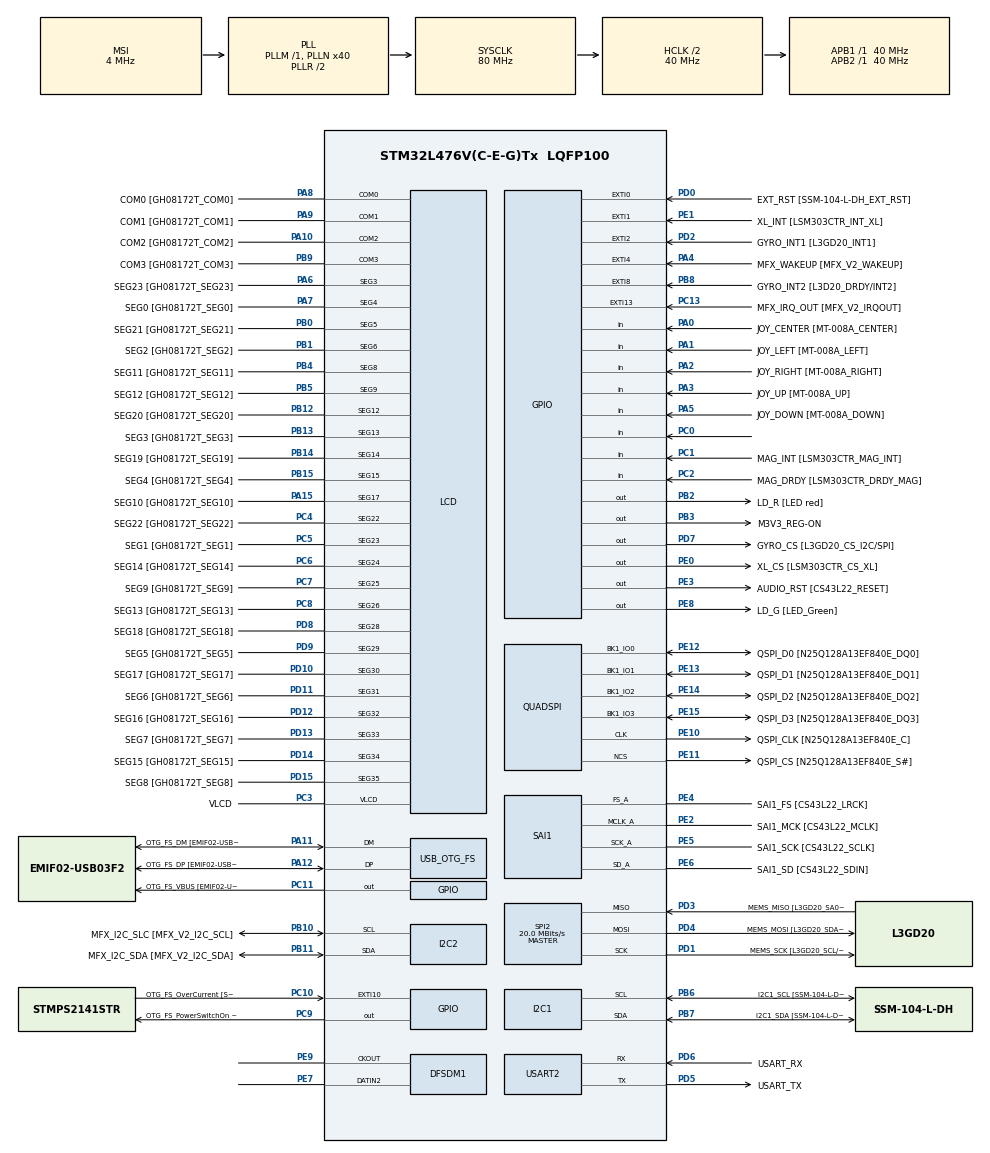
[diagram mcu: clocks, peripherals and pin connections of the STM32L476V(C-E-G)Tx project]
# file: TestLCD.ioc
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DFSDM1.Divider=4
DFSDM1.DmaMode_inj_FIL0=DISABLE
DFSDM1.DmaMode_reg_FIL0=ENABLE
DFSDM1.FastMode_reg_FIL0=ENABLE
DFSDM1.FilterOrder_CH2=DFSDM_CHANNEL_FASTSINC_ORDER
DFSDM1.Filter_injChannel2_FIL0=DFSDM_CHANNEL_2
DFSDM1.Filter_regChannel_FIL0=DFSDM_CHANNEL_2
DFSDM1.Fosr_FIL0=64
DFSDM1.Oversampling_CH2=10
DFSDM1.RightBitShift_CH2=2
DFSDM1.ScanMode_inj_FIL0=ENABLE
DFSDM1.Selection=DFSDM_CHANNEL_OUTPUT_CLOCK_AUDIO
DFSDM1.SincOrder_FIL0=DFSDM_FILTER_SINC3_ORDER
Dma.DFSDM1_FLT0.0.Direction=DMA_PERIPH_TO_MEMORY
Dma.DFSDM1_FLT0.0.Instance=DMA1_Channel4
Dma.DFSDM1_FLT0.0.MemDataAlignment=DMA_MDATAALIGN_WORD
Dma.DFSDM1_FLT0.0.MemInc=DMA_MINC_ENABLE
Dma.DFSDM1_FLT0.0.Mode=DMA_CIRCULAR
Dma.DFSDM1_FLT0.0.PeriphDataAlignment=DMA_PDATAALIGN_WORD
Dma.DFSDM1_FLT0.0.PeriphInc=DMA_PINC_DISABLE
Dma.DFSDM1_FLT0.0.Priority=DMA_PRIORITY_HIGH
Dma.Request0=DFSDM1_FLT0
Dma.Request1=SAI1_A
Dma.SAI1_A.1.Direction=DMA_MEMORY_TO_PERIPH
Dma.SAI1_A.1.Instance=DMA2_Channel1
Dma.SAI1_A.1.MemDataAlignment=DMA_MDATAALIGN_HALFWORD
Dma.SAI1_A.1.MemInc=DMA_MINC_ENABLE
Dma.SAI1_A.1.Mode=DMA_CIRCULAR
Dma.SAI1_A.1.PeriphDataAlignment=DMA_PDATAALIGN_HALFWORD
Dma.SAI1_A.1.PeriphInc=DMA_PINC_DISABLE
Dma.SAI1_A.1.Priority=DMA_PRIORITY_HIGH
I2C1.Timing=0x00909BEB
I2C2.Timing=0x00909BEB
Mcu.Family=STM32L4
Mcu.Name=STM32L476V(C-E-G)Tx
Mcu.Package=LQFP100
NVIC.DFSDM1_FLT0_IRQn=true\:0\:0\:false\:false\:true\:true\:true
NVIC.DMA1_Channel4_IRQn=true\:0\:0\:false\:false\:true\:false\:true
NVIC.DMA2_Channel1_IRQn=true\:0\:0\:false\:false\:true\:false\:true
NVIC.OTG_FS_IRQn=true\:0\:0\:false\:false\:true\:true\:true
NVIC.PriorityGroup=NVIC_PRIORITYGROUP_4
NVIC.QUADSPI_IRQn=true\:0\:0\:false\:false\:true\:true\:true
NVIC.SAI1_IRQn=true\:0\:0\:false\:false\:true\:true\:true
PA0.GPIO_Label=JOY_CENTER [MT-008A_CENTER]
PA0.GPIO_Mode=GPIO_MODE_INPUT
PA0.GPIO_PuPd=GPIO_PULLDOWN
PA0.Signal=GPIO_Input
PA1.GPIO_Label=JOY_LEFT [MT-008A_LEFT]
PA1.GPIO_Mode=GPIO_MODE_INPUT
PA1.GPIO_PuPd=GPIO_PULLDOWN
PA1.Signal=GPIO_Input
PA10.GPIO_Label=COM2 [GH08172T_COM2]
PA10.GPIO_Mode=GPIO_MODE_AF_PP
PA10.GPIO_PuPd=GPIO_NOPULL
PA10.GPIO_Speed=GPIO_SPEED_FREQ_LOW
PA10.Mode=1/4 Duty Cycle
PA10.Signal=LCD_COM2
PA11.GPIO_Label=OTG_FS_DM [EMIF02-USB03F2_D-out]
PA11.GPIO_Mode=GPIO_MODE_AF_PP
PA11.GPIO_PuPd=GPIO_NOPULL
PA11.GPIO_Speed=GPIO_SPEED_FREQ_VERY_HIGH
PA11.Mode=Host_Only
PA11.Signal=USB_OTG_FS_DM
PA12.GPIO_Label=OTG_FS_DP [EMIF02-USB03F2_D+out]
PA12.GPIO_Mode=GPIO_MODE_AF_PP
PA12.GPIO_PuPd=GPIO_NOPULL
PA12.GPIO_Speed=GPIO_SPEED_FREQ_VERY_HIGH
PA12.Mode=Host_Only
PA12.Signal=USB_OTG_FS_DP
PA13\ (JTMS-SWDIO).GPIO_Label=SWDIO
PA13\ (JTMS-SWDIO).Mode=Serial_Wire
PA13\ (JTMS-SWDIO).Signal=SYS_JTMS-SWDIO
PA14\ (JTCK-SWCLK).GPIO_Label=SWCLK
PA14\ (JTCK-SWCLK).Mode=Serial_Wire
PA14\ (JTCK-SWCLK).Signal=SYS_JTCK-SWCLK
PA15\ (JTDI).GPIO_Label=SEG10 [GH08172T_SEG10]
PA15\ (JTDI).GPIO_Mode=GPIO_MODE_AF_PP
PA15\ (JTDI).GPIO_PuPd=GPIO_NOPULL
PA15\ (JTDI).GPIO_Speed=GPIO_SPEED_FREQ_LOW
PA15\ (JTDI).Mode=SEG17
PA15\ (JTDI).Signal=LCD_SEG17
PA2.GPIO_Label=JOY_RIGHT [MT-008A_RIGHT]
PA2.GPIO_Mode=GPIO_MODE_INPUT
PA2.GPIO_PuPd=GPIO_PULLDOWN
PA2.Signal=GPIO_Input
PA3.GPIO_Label=JOY_UP [MT-008A_UP]
PA3.GPIO_Mode=GPIO_MODE_INPUT
PA3.GPIO_PuPd=GPIO_PULLDOWN
PA3.Signal=GPIO_Input
PA4.GPIO_Label=MFX_WAKEUP [MFX_V2_WAKEUP]
PA4.GPIO_ModeDefaultEXTI=GPIO_MODE_EVT_RISING
PA4.GPIO_PuPd=GPIO_NOPULL
PA4.Signal=GPXTI4
PA5.GPIO_Label=JOY_DOWN [MT-008A_DOWN]
PA5.GPIO_Mode=GPIO_MODE_INPUT
PA5.GPIO_PuPd=GPIO_PULLDOWN
PA5.Signal=GPIO_Input
PA6.GPIO_Label=SEG23 [GH08172T_SEG23]
PA6.GPIO_Mode=GPIO_MODE_AF_PP
PA6.GPIO_PuPd=GPIO_NOPULL
PA6.GPIO_Speed=GPIO_SPEED_FREQ_LOW
PA6.Mode=SEG3
PA6.Signal=LCD_SEG3
PA7.GPIO_Label=SEG0 [GH08172T_SEG0]
PA7.GPIO_Mode=GPIO_MODE_AF_PP
PA7.GPIO_PuPd=GPIO_NOPULL
PA7.GPIO_Speed=GPIO_SPEED_FREQ_LOW
PA7.Mode=SEG4
PA7.Signal=LCD_SEG4
PA8.GPIO_Label=COM0 [GH08172T_COM0]
PA8.GPIO_Mode=GPIO_MODE_AF_PP
PA8.GPIO_PuPd=GPIO_NOPULL
PA8.GPIO_Speed=GPIO_SPEED_FREQ_LOW
PA8.Mode=1/4 Duty Cycle
PA8.Signal=LCD_COM0
PA9.GPIO_Label=COM1 [GH08172T_COM1]
PA9.GPIO_Mode=GPIO_MODE_AF_PP
PA9.GPIO_PuPd=GPIO_NOPULL
PA9.GPIO_Speed=GPIO_SPEED_FREQ_LOW
PA9.Mode=1/4 Duty Cycle
PA9.Signal=LCD_COM1
PB0.GPIO_Label=SEG21 [GH08172T_SEG21]
PB0.GPIO_Mode=GPIO_MODE_AF_PP
PB0.GPIO_PuPd=GPIO_NOPULL
PB0.GPIO_Speed=GPIO_SPEED_FREQ_LOW
PB0.Mode=SEG5
PB0.Signal=LCD_SEG5
PB1.GPIO_Label=SEG2 [GH08172T_SEG2]
PB1.GPIO_Mode=GPIO_MODE_AF_PP
PB1.GPIO_PuPd=GPIO_NOPULL
PB1.GPIO_Speed=GPIO_SPEED_FREQ_LOW
PB1.Mode=SEG6
PB1.Signal=LCD_SEG6
PB10.GPIO_Label=MFX_I2C_SLC [MFX_V2_I2C_SCL]
PB10.GPIO_Mode=GPIO_MODE_AF_OD
PB10.GPIO_PuPdOD=GPIO_PULLUP
PB10.GPIO_Speed=GPIO_SPEED_FREQ_VERY_HIGH
PB10.Mode=I2C
PB10.Signal=I2C2_SCL
PB11.GPIO_Label=MFX_I2C_SDA [MFX_V2_I2C_SDA]
PB11.GPIO_Mode=GPIO_MODE_AF_OD
PB11.GPIO_PuPdOD=GPIO_PULLUP
PB11.GPIO_Speed=GPIO_SPEED_FREQ_VERY_HIGH
PB11.Mode=I2C
PB11.Signal=I2C2_SDA
PB12.GPIO_Label=SEG20 [GH08172T_SEG20]
PB12.GPIO_Mode=GPIO_MODE_AF_PP
PB12.GPIO_PuPd=GPIO_NOPULL
PB12.GPIO_Speed=GPIO_SPEED_FREQ_LOW
PB12.Mode=SEG12
PB12.Signal=LCD_SEG12
PB13.GPIO_Label=SEG3 [GH08172T_SEG3]
PB13.GPIO_Mode=GPIO_MODE_AF_PP
PB13.GPIO_PuPd=GPIO_NOPULL
PB13.GPIO_Speed=GPIO_SPEED_FREQ_LOW
PB13.Mode=SEG13
PB13.Signal=LCD_SEG13
PB14.GPIO_Label=SEG19 [GH08172T_SEG19]
PB14.GPIO_Mode=GPIO_MODE_AF_PP
PB14.GPIO_PuPd=GPIO_NOPULL
PB14.GPIO_Speed=GPIO_SPEED_FREQ_LOW
PB14.Mode=SEG14
PB14.Signal=LCD_SEG14
PB15.GPIO_Label=SEG4 [GH08172T_SEG4]
PB15.GPIO_Mode=GPIO_MODE_AF_PP
PB15.GPIO_PuPd=GPIO_NOPULL
PB15.GPIO_Speed=GPIO_SPEED_FREQ_LOW
PB15.Mode=SEG15
PB15.Signal=LCD_SEG15
PB2.GPIO_Label=LD_R [LED red]
PB2.GPIO_ModeDefaultOutputPP=GPIO_MODE_OUTPUT_PP
PB2.GPIO_PuPd=GPIO_PULLUP
PB2.GPIO_Speed=GPIO_SPEED_FREQ_VERY_HIGH
PB2.Signal=GPIO_Output
PB3\ (JTDO-TRACESWO).GPIO_Label=M3V3_REG-ON
PB3\ (JTDO-TRACESWO).GPIO_ModeDefaultOutputPP=GPIO_MODE_OUTPUT_PP
PB3\ (JTDO-TRACESWO).GPIO_PuPd=GPIO_NOPULL
PB3\ (JTDO-TRACESWO).GPIO_Speed=GPIO_SPEED_FREQ_LOW
PB3\ (JTDO-TRACESWO).Signal=GPIO_Output
PB4\ (NJTRST).GPIO_Label=SEG11 [GH08172T_SEG11]
PB4\ (NJTRST).GPIO_Mode=GPIO_MODE_AF_PP
PB4\ (NJTRST).GPIO_PuPd=GPIO_NOPULL
PB4\ (NJTRST).GPIO_Speed=GPIO_SPEED_FREQ_LOW
PB4\ (NJTRST).Mode=SEG8
PB4\ (NJTRST).Signal=LCD_SEG8
PB5.GPIO_Label=SEG12 [GH08172T_SEG12]
PB5.GPIO_Mode=GPIO_MODE_AF_PP
PB5.GPIO_PuPd=GPIO_NOPULL
PB5.GPIO_Speed=GPIO_SPEED_FREQ_LOW
PB5.Mode=SEG9
PB5.Signal=LCD_SEG9
PB6.GPIO_FM6=__NULL
PB6.GPIO_Label=I2C1_SCL [SSM-104-L-DH_SCL]
PB6.GPIO_Mode=GPIO_MODE_AF_OD
PB6.GPIO_PuPdOD=GPIO_PULLUP
PB6.GPIO_Speed=GPIO_SPEED_FREQ_VERY_HIGH
PB6.Mode=I2C
PB6.Signal=I2C1_SCL
PB7.GPIO_FM7=__NULL
PB7.GPIO_Label=I2C1_SDA [SSM-104-L-DH_SDA]
PB7.GPIO_Mode=GPIO_MODE_AF_OD
PB7.GPIO_PuPdOD=GPIO_PULLUP
PB7.GPIO_Speed=GPIO_SPEED_FREQ_VERY_HIGH
PB7.Mode=I2C
PB7.Signal=I2C1_SDA
PB8.GPIO_Label=GYRO_INT2 [L3D20_DRDY/INT2]
PB8.GPIO_ModeDefaultEXTI=GPIO_MODE_EVT_RISING
PB8.GPIO_PuPd=GPIO_NOPULL
PB8.Signal=GPXTI8
PB9.GPIO_FM9=__NULL
PB9.GPIO_Label=COM3 [GH08172T_COM3]
PB9.GPIO_Mode=GPIO_MODE_AF_PP
PB9.GPIO_PuPd=GPIO_NOPULL
PB9.GPIO_Speed=GPIO_SPEED_FREQ_LOW
PB9.Mode=1/4 Duty Cycle
PB9.Signal=LCD_COM3
PC0.Signal=GPIO_Input
PC1.GPIO_Label=MAG_INT [LSM303CTR_MAG_INT]
PC1.GPIO_Mode=GPIO_MODE_INPUT
PC1.GPIO_PuPd=GPIO_NOPULL
PC1.Signal=GPIO_Input
PC10.GPIO_Label=OTG_FS_OverCurrent [STMPS2141STR_FAULT]
PC10.GPIO_ModeDefaultEXTI=GPIO_MODE_EVT_RISING
PC10.GPIO_PuPd=GPIO_NOPULL
PC10.Signal=GPXTI10
PC11.GPIO_Label=OTG_FS_VBUS [EMIF02-USB03F2_Vbus]
PC11.GPIO_ModeDefaultOutputPP=GPIO_MODE_OUTPUT_PP
PC11.GPIO_PuPd=GPIO_NOPULL
PC11.GPIO_Speed=GPIO_SPEED_FREQ_LOW
PC11.Signal=GPIO_Output
PC13.GPIO_Label=MFX_IRQ_OUT [MFX_V2_IRQOUT]
PC13.GPIO_ModeDefaultEXTI=GPIO_MODE_EVT_RISING
PC13.GPIO_PuPd=GPIO_NOPULL
PC13.Signal=GPXTI13
PC14-OSC32_IN\ (PC14).Mode=LSE-External-Oscillator
PC14-OSC32_IN\ (PC14).Signal=RCC_OSC32_IN
PC15-OSC32_OUT\ (PC15).Mode=LSE-External-Oscillator
PC15-OSC32_OUT\ (PC15).Signal=RCC_OSC32_OUT
PC2.GPIO_Label=MAG_DRDY [LSM303CTR_DRDY_MAG]
PC2.GPIO_Mode=GPIO_MODE_INPUT
PC2.GPIO_PuPd=GPIO_NOPULL
PC2.Signal=GPIO_Input
PC3.GPIO_Label=VLCD
PC3.GPIO_Mode=GPIO_MODE_AF_PP
PC3.GPIO_PuPd=GPIO_NOPULL
PC3.GPIO_Speed=GPIO_SPEED_FREQ_LOW
PC3.Mode=1/4 Duty Cycle
PC3.Signal=LCD_VLCD
PC4.GPIO_Label=SEG22 [GH08172T_SEG22]
PC4.GPIO_Mode=GPIO_MODE_AF_PP
PC4.GPIO_PuPd=GPIO_NOPULL
PC4.GPIO_Speed=GPIO_SPEED_FREQ_LOW
PC4.Mode=SEG22
PC4.Signal=LCD_SEG22
PC5.GPIO_Label=SEG1 [GH08172T_SEG1]
PC5.GPIO_Mode=GPIO_MODE_AF_PP
PC5.GPIO_PuPd=GPIO_NOPULL
PC5.GPIO_Speed=GPIO_SPEED_FREQ_LOW
PC5.Mode=SEG23
PC5.Signal=LCD_SEG23
PC6.GPIO_Label=SEG14 [GH08172T_SEG14]
PC6.GPIO_Mode=GPIO_MODE_AF_PP
PC6.GPIO_PuPd=GPIO_NOPULL
PC6.GPIO_Speed=GPIO_SPEED_FREQ_LOW
PC6.Mode=SEG24
PC6.Signal=LCD_SEG24
PC7.GPIO_Label=SEG9 [GH08172T_SEG9]
PC7.GPIO_Mode=GPIO_MODE_AF_PP
PC7.GPIO_PuPd=GPIO_NOPULL
PC7.GPIO_Speed=GPIO_SPEED_FREQ_LOW
PC7.Mode=SEG25
PC7.Signal=LCD_SEG25
PC8.GPIO_Label=SEG13 [GH08172T_SEG13]
PC8.GPIO_Mode=GPIO_MODE_AF_PP
PC8.GPIO_PuPd=GPIO_NOPULL
PC8.GPIO_Speed=GPIO_SPEED_FREQ_LOW
PC8.Mode=SEG26
PC8.Signal=LCD_SEG26
PC9.GPIO_Label=OTG_FS_PowerSwitchOn [STMPS2141STR_EN]
PC9.GPIO_ModeDefaultOutputPP=GPIO_MODE_OUTPUT_PP
PC9.GPIO_PuPd=GPIO_NOPULL
PC9.GPIO_Speed=GPIO_SPEED_FREQ_LOW
PC9.PinState=GPIO_PIN_SET
PC9.Signal=GPIO_Output
PD0.GPIO_Label=EXT_RST [SSM-104-L-DH_EXT_RST]
PD0.GPIO_ModeDefaultEXTI=GPIO_MODE_EVT_RISING
PD0.GPIO_PuPd=GPIO_NOPULL
PD0.Signal=GPXTI0
PD1.GPIO_Label=MEMS_SCK [L3GD20_SCL/SPC]
PD1.GPIO_Mode=GPIO_MODE_AF_PP
PD1.GPIO_PuPd=GPIO_NOPULL
PD1.GPIO_Speed=GPIO_SPEED_FREQ_VERY_HIGH
PD1.Mode=Full_Duplex_Master
PD1.Signal=SPI2_SCK
PD10.GPIO_Label=SEG17 [GH08172T_SEG17]
PD10.GPIO_Mode=GPIO_MODE_AF_PP
PD10.GPIO_PuPd=GPIO_NOPULL
PD10.GPIO_Speed=GPIO_SPEED_FREQ_LOW
PD10.Mode=SEG30
PD10.Signal=LCD_SEG30
PD11.GPIO_Label=SEG6 [GH08172T_SEG6]
PD11.GPIO_Mode=GPIO_MODE_AF_PP
PD11.GPIO_PuPd=GPIO_NOPULL
PD11.GPIO_Speed=GPIO_SPEED_FREQ_LOW
PD11.Mode=SEG31
PD11.Signal=LCD_SEG31
PD12.GPIO_Label=SEG16 [GH08172T_SEG16]
PD12.GPIO_Mode=GPIO_MODE_AF_PP
PD12.GPIO_PuPd=GPIO_NOPULL
PD12.GPIO_Speed=GPIO_SPEED_FREQ_LOW
PD12.Mode=SEG32
PD12.Signal=LCD_SEG32
PD13.GPIO_Label=SEG7 [GH08172T_SEG7]
PD13.GPIO_Mode=GPIO_MODE_AF_PP
PD13.GPIO_PuPd=GPIO_NOPULL
PD13.GPIO_Speed=GPIO_SPEED_FREQ_LOW
PD13.Mode=SEG33
PD13.Signal=LCD_SEG33
PD14.GPIO_Label=SEG15 [GH08172T_SEG15]
PD14.GPIO_Mode=GPIO_MODE_AF_PP
PD14.GPIO_PuPd=GPIO_NOPULL
PD14.GPIO_Speed=GPIO_SPEED_FREQ_LOW
PD14.Mode=SEG34
PD14.Signal=LCD_SEG34
PD15.GPIO_Label=SEG8 [GH08172T_SEG8]
PD15.GPIO_Mode=GPIO_MODE_AF_PP
PD15.GPIO_PuPd=GPIO_NOPULL
PD15.GPIO_Speed=GPIO_SPEED_FREQ_LOW
PD15.Mode=SEG35
PD15.Signal=LCD_SEG35
PD2.GPIO_Label=GYRO_INT1 [L3GD20_INT1]
PD2.GPIO_ModeDefaultEXTI=GPIO_MODE_EVT_RISING
PD2.GPIO_PuPd=GPIO_NOPULL
PD2.Signal=GPXTI2
PD3.GPIO_Label=MEMS_MISO [L3GD20_SA0/SDO]
PD3.GPIO_Mode=GPIO_MODE_AF_PP
PD3.GPIO_PuPd=GPIO_NOPULL
PD3.GPIO_Speed=GPIO_SPEED_FREQ_VERY_HIGH
PD3.Mode=Full_Duplex_Master
PD3.Signal=SPI2_MISO
PD4.GPIO_Label=MEMS_MOSI [L3GD20_SDA/SDI/SDO]
PD4.GPIO_Mode=GPIO_MODE_AF_PP
PD4.GPIO_PuPd=GPIO_NOPULL
PD4.GPIO_Speed=GPIO_SPEED_FREQ_VERY_HIGH
PD4.Mode=Full_Duplex_Master
PD4.Signal=SPI2_MOSI
PD5.GPIO_Label=USART_TX
PD5.GPIO_Mode=GPIO_MODE_AF_PP
PD5.GPIO_PuPd=GPIO_PULLUP
PD5.GPIO_Speed=GPIO_SPEED_FREQ_VERY_HIGH
PD5.Mode=Asynchronous
PD5.Signal=USART2_TX
PD6.GPIO_Label=USART_RX
PD6.GPIO_Mode=GPIO_MODE_AF_PP
PD6.GPIO_PuPd=GPIO_PULLUP
PD6.GPIO_Speed=GPIO_SPEED_FREQ_VERY_HIGH
PD6.Mode=Asynchronous
PD6.Signal=USART2_RX
PD7.GPIO_Label=GYRO_CS [L3GD20_CS_I2C/SPI]
PD7.GPIO_ModeDefaultOutputPP=GPIO_MODE_OUTPUT_PP
PD7.GPIO_PuPd=GPIO_NOPULL
PD7.GPIO_Speed=GPIO_SPEED_FREQ_VERY_HIGH
PD7.Signal=GPIO_Output
PD8.GPIO_Label=SEG18 [GH08172T_SEG18]
PD8.GPIO_Mode=GPIO_MODE_AF_PP
PD8.GPIO_PuPd=GPIO_NOPULL
PD8.GPIO_Speed=GPIO_SPEED_FREQ_LOW
PD8.Mode=SEG28
PD8.Signal=LCD_SEG28
PD9.GPIO_Label=SEG5 [GH08172T_SEG5]
PD9.GPIO_Mode=GPIO_MODE_AF_PP
PD9.GPIO_PuPd=GPIO_NOPULL
PD9.GPIO_Speed=GPIO_SPEED_FREQ_LOW
PD9.Mode=SEG29
PD9.Signal=LCD_SEG29
PE0.GPIO_Label=XL_CS [LSM303CTR_CS_XL]
PE0.GPIO_ModeDefaultOutputPP=GPIO_MODE_OUTPUT_PP
PE0.GPIO_PuPd=GPIO_NOPULL
PE0.GPIO_Speed=GPIO_SPEED_FREQ_LOW
PE0.Signal=GPIO_Output
PE1.GPIO_Label=XL_INT [LSM303CTR_INT_XL]
PE1.GPIO_ModeDefaultEXTI=GPIO_MODE_EVT_RISING
PE1.GPIO_PuPd=GPIO_NOPULL
PE1.Signal=GPXTI1
PE10.GPIO_Label=QSPI_CLK [N25Q128A13EF840E_C]
PE10.GPIO_Mode=GPIO_MODE_AF_PP
PE10.GPIO_PuPd=GPIO_NOPULL
PE10.GPIO_Speed=GPIO_SPEED_FREQ_VERY_HIGH
PE10.Mode=Single Bank
PE10.Signal=QUADSPI_CLK
PE11.GPIO_Label=QSPI_CS [N25Q128A13EF840E_S\#]
PE11.GPIO_Mode=GPIO_MODE_AF_PP
PE11.GPIO_PuPd=GPIO_NOPULL
PE11.GPIO_Speed=GPIO_SPEED_FREQ_VERY_HIGH
PE11.Mode=Single Bank
PE11.Signal=QUADSPI_NCS
PE12.GPIO_Label=QSPI_D0 [N25Q128A13EF840E_DQ0]
PE12.GPIO_Mode=GPIO_MODE_AF_PP
PE12.GPIO_PuPd=GPIO_NOPULL
PE12.GPIO_Speed=GPIO_SPEED_FREQ_VERY_HIGH
PE12.Mode=Single Bank
PE12.Signal=QUADSPI_BK1_IO0
PE13.GPIO_Label=QSPI_D1 [N25Q128A13EF840E_DQ1]
PE13.GPIO_Mode=GPIO_MODE_AF_PP
PE13.GPIO_PuPd=GPIO_NOPULL
PE13.GPIO_Speed=GPIO_SPEED_FREQ_VERY_HIGH
PE13.Mode=Single Bank
PE13.Signal=QUADSPI_BK1_IO1
PE14.GPIO_Label=QSPI_D2 [N25Q128A13EF840E_DQ2]
PE14.GPIO_Mode=GPIO_MODE_AF_PP
PE14.GPIO_PuPd=GPIO_NOPULL
PE14.GPIO_Speed=GPIO_SPEED_FREQ_VERY_HIGH
PE14.Mode=Single Bank
PE14.Signal=QUADSPI_BK1_IO2
PE15.GPIO_Label=QSPI_D3 [N25Q128A13EF840E_DQ3]
PE15.GPIO_Mode=GPIO_MODE_AF_PP
PE15.GPIO_PuPd=GPIO_NOPULL
PE15.GPIO_Speed=GPIO_SPEED_FREQ_VERY_HIGH
PE15.Mode=Single Bank
PE15.Signal=QUADSPI_BK1_IO3
PE2.GPIO_Label=SAI1_MCK [CS43L22_MCLK]
PE2.GPIO_Mode=GPIO_MODE_AF_PP
PE2.GPIO_PuPd=GPIO_NOPULL
PE2.GPIO_Speed=GPIO_SPEED_FREQ_VERY_HIGH
PE2.Mode=SAI_A_MasterWithClock
PE2.Signal=SAI1_MCLK_A
PE3.GPIO_Label=AUDIO_RST [CS43L22_RESET]
PE3.GPIO_ModeDefaultOutputPP=GPIO_MODE_OUTPUT_PP
PE3.GPIO_PuPd=GPIO_NOPULL
PE3.GPIO_Speed=GPIO_SPEED_FREQ_HIGH
PE3.Signal=GPIO_Output
PE4.GPIO_Label=SAI1_FS [CS43L22_LRCK]
PE4.GPIO_Mode=GPIO_MODE_AF_PP
PE4.GPIO_PuPd=GPIO_NOPULL
PE4.GPIO_Speed=GPIO_SPEED_FREQ_VERY_HIGH
PE4.Mode=SAI_A_MasterWithClock
PE4.Signal=SAI1_FS_A
PE5.GPIO_Label=SAI1_SCK [CS43L22_SCLK]
PE5.GPIO_Mode=GPIO_MODE_AF_PP
PE5.GPIO_PuPd=GPIO_NOPULL
PE5.GPIO_Speed=GPIO_SPEED_FREQ_VERY_HIGH
PE5.Mode=SAI_A_MasterWithClock
PE5.Signal=SAI1_SCK_A
PE6.GPIO_Label=SAI1_SD [CS43L22_SDIN]
PE6.GPIO_Mode=GPIO_MODE_AF_PP
PE6.GPIO_PuPd=GPIO_NOPULL
PE6.GPIO_Speed=GPIO_SPEED_FREQ_VERY_HIGH
PE6.Mode=SAI_A_MasterWithClock
PE6.Signal=SAI1_SD_A
PE7.Signal=S_DATAIN2DFSDM1
PE8.GPIO_Label=LD_G [LED_Green]
PE8.GPIO_ModeDefaultOutputPP=GPIO_MODE_OUTPUT_PP
PE8.GPIO_PuPd=GPIO_PULLUP
PE8.GPIO_Speed=GPIO_SPEED_FREQ_VERY_HIGH
PE8.Signal=GPIO_Output
PE9.Signal=S_CKOUTDFSDM1
PH0-OSC_IN\ (PH0).Mode=HSE-External-Oscillator
PH0-OSC_IN\ (PH0).Signal=RCC_OSC_IN
PH1-OSC_OUT\ (PH1).Mode=HSE-External-Oscillator
PH1-OSC_OUT\ (PH1).Signal=RCC_OSC_OUT
ProjectManager.HeapSize=0x200
ProjectManager.StackSize=0x400
ProjectManager.TargetToolchain=STM32CubeIDE
QUADSPI.ChipSelectHighTime-Single\ Bank=QSPI_CS_HIGH_TIME_1_CYCLE
QUADSPI.ClockMode-Single\ Bank=QSPI_CLOCK_MODE_0
QUADSPI.ClockPrescaler-Single\ Bank=0
QUADSPI.FifoThreshold-Single\ Bank=4
QUADSPI.FlashSize-Single\ Bank=24
QUADSPI.SampleShifting-Single\ Bank=QSPI_SAMPLE_SHIFTING_HALFCYCLE
RCC.ADCFreq_Value=96000000
RCC.AHBCLKDivider=RCC_SYSCLK_DIV2
RCC.AHBFreq_Value=40000000
RCC.APB1Freq_Value=40000000
RCC.APB1TimFreq_Value=40000000
RCC.APB2Freq_Value=40000000
RCC.APB2TimFreq_Value=40000000
RCC.CortexFreq_Value=40000000
RCC.HCLKFreq_Value=40000000
RCC.HSE_VALUE=8000000
RCC.HSI_VALUE=16000000
RCC.MSI_VALUE=4000000
RCC.PLLN=40
RCC.PLLQ=RCC_PLLQ_DIV4
RCC.PLLSAI1N=48
RCC.PLLSAI1P=RCC_PLLP_DIV17
RCC.PLLSAI1Q=RCC_PLLQ_DIV4
RCC.PREFETCH_ENABLE=1
RCC.SYSCLKFreq_VALUE=80000000
RCC.SYSCLKSource=RCC_SYSCLKSOURCE_PLLCLK
RCC.USBFreq_Value=48000000
RCC.VCOOutputFreq_Value=160000000
SAI1.ActiveFrameLength-SAI_A_MasterWithClock=16
SAI1.AudioFrequency-SAI_A_MasterWithClock=SAI_AUDIO_FREQUENCY_44K
SAI1.DataSize-SAI_A_MasterWithClock=SAI_DATASIZE_16
SAI1.ErrorAudioFreq-SAI_A_MasterWithClock=0.26 %
SAI1.FIFOThreshold-SAI_A_MasterWithClock=SAI_FIFOTHRESHOLD_1QF
SAI1.FSDefinition-SAI_A_MasterWithClock=SAI_FS_CHANNEL_IDENTIFICATION
SAI1.FSOffset-SAI_A_MasterWithClock=SAI_FS_BEFOREFIRSTBIT
SAI1.FrameLength-SAI_A_MasterWithClock=32
SAI1.Instance-SAI_A_MasterWithClock=SAI$Index_Block_A
SAI1.MClockEnable-SAI_A_MasterWithClock=SAI_MASTERCLOCK_ENABLE
SAI1.MonoStereoMode-SAI_A_MasterWithClock=SAI_STEREOMODE
SAI1.OutputDrive-SAI_A_MasterWithClock=SAI_OUTPUTDRIVE_ENABLE
SAI1.RealAudioFreq-SAI_A_MasterWithClock=44.117 KHz
SAI1.SlotActive-SAI_A_MasterWithClock=0x00000003
SAI1.SlotNumber-SAI_A_MasterWithClock=2
SAI1.VirtualMode-SAI_A_MasterWithClock=VM_MASTER
SAI1.VirtualSlotActive-SAI_A_MasterWithClock=SAI_SLOT_USERSETTING
SAI1.VirtualSlotActive0-SAI_A_MasterWithClock=true
SAI1.VirtualSlotActive1-SAI_A_MasterWithClock=true
SH.S_CKOUTDFSDM1.0=DFSDM1_CKOUT,PDM_SPI_input_from_ch2_and_internal_clock
SH.S_DATAIN2DFSDM1.0=DFSDM1_DATIN2,PDM_SPI_input_from_ch2_and_internal_clock
SPI2.CalculateBaudRate=20.0 MBits/s
SPI2.Direction=SPI_DIRECTION_2LINES
SPI2.Mode=SPI_MODE_MASTER
SPI2.VirtualType=VM_MASTER
USART2.VirtualMode-Asynchronous=VM_ASYNC
USB_HOST.BSP.number=1
USB_HOST.USBH_HandleTypeDef=hUsbHostFS
USB_HOST.VirtualModeFS=Cdc
USB_HOST0.BSP.STBoard=false
USB_HOST0.BSP.api=Unknown
USB_HOST0.BSP.i2caddr=0
USB_HOST0.BSP.i2creg=0
USB_HOST0.BSP.instance=PC9
USB_HOST0.BSP.ip=GPIO
USB_HOST0.BSP.mode=Output
USB_HOST0.BSP.name=Drive_VBUS_FS
USB_HOST0.BSP.solution=PC9
USB_OTG_FS.VirtualMode=Host_Only
USB_OTG_FS.phy_itface=HCD_PHY_EMBEDDED
VP_USB_HOST_VS_USB_HOST_CDC_FS.Mode=CDC_FS
board=STM32L476G-DISCO

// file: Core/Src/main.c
/* USER CODE BEGIN Header */
/**
  ******************************************************************************
  * @file           : main.c
  * @brief          : Main program body
  ******************************************************************************
  * @attention
  *
  * <h2><center>&copy; Copyright (c) 2022 STMicroelectronics.
  * All rights reserved.</center></h2>
  *
  * This software component is licensed by ST under Ultimate Liberty license
  * SLA0044, the "License"; You may not use this file except in compliance with
  * the License. You may obtain a copy of the License at:
  *                             www.st.com/SLA0044
  *
  ******************************************************************************
  */
/* USER CODE END Header */
#include "main.h"
#include "dfsdm.h"
#include "dma.h"
#include "i2c.h"
#include "lcd.h"
#include "quadspi.h"
#include "sai.h"
#include "spi.h"
#include "usart.h"
#include "usb_host.h"
#include "gpio.h"

/* USER CODE BEGIN Includes */
#include "stm32l476g_discovery_glass_lcd.h"
#include "audio.h"
#include "cs43l22.h"
#include "stm32l476g_discovery_qspi.h"
#include "stm32l476g_discovery.h"
#include "string.h"
/* USER CODE END Includes */

/* USER CODE BEGIN PD */
#define SaturaLH(N, L, H) (((N)<(L))?(L):(((N)>(H))?(H):(N)))
#define BUFFER_SIZE         ((uint32_t)0x800) // 2048 bajtów
#define WRITE_READ_ADDR     ((uint32_t)0x0000)
#define QSPI_BASE_ADDR      ((uint32_t)0x90000000)
/* USER CODE END PD */

/* USER CODE BEGIN PV */
AUDIO_DrvTypeDef            *audio_drv;
uint32_t                     DmaRecHalfBuffCplt  = 0;
uint32_t                     DmaRecBuffCplt      = 0;
extern DFSDM_Filter_HandleTypeDef hdfsdm1_filter0;
extern DFSDM_Channel_HandleTypeDef hdfsdm1_channel2;
extern SAI_HandleTypeDef hsai_BlockA1;
extern DMA_HandleTypeDef hdma_sai1_a;
int32_t                      RecBuff[2048];
int16_t                      PlayBuff[4096];
int16_t 					filter_arr[4096];
uint32_t                     PlaybackStarted         = 0;
volatile int 				tryb = -1;//
int flag = 0;
static QSPI_Info pQSPI_Info;

/* USER CODE END PV */

void SystemClock_Config(void);
void MX_USB_HOST_Process(void);

int main(void)
{
  /* USER CODE BEGIN 1 */
  uint32_t i;
  int index_cpy = 0;
  /* USER CODE END 1 */

  /* MCU Configuration--------------------------------------------------------*/

  /* Reset of all peripherals, Initializes the Flash interface and the Systick. */
  HAL_Init();

  /* Configure the system clock */
  SystemClock_Config();

  /* USER CODE BEGIN SysInit */
  MX_DMA_Init();
  /* USER CODE END SysInit */

  /* Initialize all configured peripherals */
  MX_GPIO_Init();
  //MX_DMA_Init();
  MX_I2C1_Init();
  MX_I2C2_Init();
  MX_LCD_Init();
  MX_QUADSPI_Init();
  MX_SAI1_Init();
  MX_SPI2_Init();
  MX_USART2_UART_Init();
  MX_USB_HOST_Init();
  MX_DFSDM1_Init();
  /* USER CODE BEGIN 2 */
  if(HAL_OK != HAL_DFSDM_FilterRegularStart_DMA(&hdfsdm1_filter0, RecBuff, 2048))
    {
         Error_Handler();
     }

  __HAL_SAI_ENABLE(&hsai_BlockA1);

      if(CS43L22_ID != cs43l22_drv.ReadID(AUDIO_I2C_ADDRESS))
        {
          Error_Handler();
        }
      	audio_drv = &cs43l22_drv;
        audio_drv->Reset(AUDIO_I2C_ADDRESS);
        if(0 != audio_drv->Init(AUDIO_I2C_ADDRESS, OUTPUT_DEVICE_HEADPHONE, 90, AUDIO_FREQUENCY_44K))
        {
          Error_Handler();
        }

        BSP_LCD_GLASS_Init();

        if (QSPI_OK == BSP_QSPI_Init())
        {
      	  pQSPI_Info.FlashSize          = (uint32_t)0x00;
      	  pQSPI_Info.EraseSectorSize    = (uint32_t)0x00;
      	  pQSPI_Info.EraseSectorsNumber = (uint32_t)0x00;
      	  pQSPI_Info.ProgPageSize       = (uint32_t)0x00;
      	  pQSPI_Info.ProgPagesNumber    = (uint32_t)0x00;
      	  /* Read the QSPI memory info */
      	  BSP_QSPI_GetInfo(&pQSPI_Info);

      	  /* Test the correctness */
      	  if((pQSPI_Info.FlashSize != 0x1000000) || (pQSPI_Info.EraseSectorSize != 0x1000)  ||
      	    (pQSPI_Info.ProgPageSize != 0x100)  || (pQSPI_Info.EraseSectorsNumber != 4096) ||
      	    (pQSPI_Info.ProgPagesNumber != 65536))
      	  {
      		  BSP_LCD_GLASS_ScrollSentence((uint8_t *)"      QSPI GET INFO : FAILED.", 1, SCROLL_SPEED_HIGH);
      	  }
      	  else
      	  {
      		  /*##-3- Erase QSPI memory ################################################*/
      		  if(BSP_QSPI_Erase_Block(WRITE_READ_ADDR) != QSPI_OK)
      		  {
      			  BSP_LCD_GLASS_ScrollSentence((uint8_t *)"      QSPI ERASE : FAILED.", 1, SCROLL_SPEED_HIGH);
      	      }
      	  }
        }

        int index = 0; //ilosc wiadomosci

      //  BSP_QSPI_Erase_Chip();

//      for (uint32_t l = 0; l < 256; l++){
//
//        if(BSP_QSPI_Erase_Sector(l) != QSPI_OK)
//        {
//      	  Error_Handler();
//        }
//      }

  /* USER CODE END 2 */

  /* Infinite loop */
  /* USER CODE BEGIN WHILE */
  while (1)
  {

	  if (tryb == -1)
	  {
		  BSP_LCD_GLASS_DisplayString((uint8_t *)"WITAM");
	  }
      	  switch(BSP_JOY_GetState())
      	  {
      	  case JOY_DOWN: //tryb odtwarzania
      		  tryb = 0;
      		  break;
      	  case JOY_UP:
      		  tryb = 1;
      		  break;
      	  }
      	  while(tryb == 0) // nagrywanie
      	  {
      		  BSP_LCD_GLASS_DisplayString("NAGRAJ");
      		  if(BSP_JOY_GetState() == JOY_SEL)
      		  {
      			  BSP_LCD_GLASS_Clear();
      			  tryb = 3; // wybranie slota albo zaczecie nagrywania
      			  HAL_Delay(200);
      		  }
      		  else if (BSP_JOY_GetState() == JOY_DOWN || BSP_JOY_GetState() == JOY_UP)
      		  {
      			  tryb = 1;
      			  HAL_Delay(200);
      		  }
      	  }
      	  while(tryb == 1) //odtwarzanie
      	  {
      		  BSP_LCD_GLASS_DisplayString("ODTWORZ");
      		  if(BSP_JOY_GetState() == JOY_SEL)
      		  {
      			  BSP_LCD_GLASS_Clear();
      			  tryb = 2; // wybranie wiadomości
      			  HAL_Delay(200);
      		  }
      		  else if (BSP_JOY_GetState() == JOY_DOWN || BSP_JOY_GetState() == JOY_UP)
      		  {
      			  tryb = 0;
      			  HAL_Delay(200);
      		  }
      	  }
      	  while(tryb == 2)
      	  {
      		 if (index == 0)
      		 {
      			 BSP_LCD_GLASS_ScrollSentence((uint8_t *)"      NIE MA WIADOMOSCI.", 1, SCROLL_SPEED_HIGH);
      			 tryb = 1;
      		 }
      		  uint8_t str_index[8];
      		  sprintf(str_index, "Wiad %d", index_cpy);
      		  BSP_LCD_GLASS_DisplayString(str_index);
      		  if(BSP_JOY_GetState() == JOY_UP)
      		  {
      			  if(index_cpy < 9 && index_cpy < index)
      			  {
      				  index_cpy++;
      				  HAL_Delay(200);
      				BSP_LCD_GLASS_Clear();
      			  }
      		  }
      		  if(BSP_JOY_GetState() == JOY_DOWN)
      		  {
      			  if(index_cpy > 1)
      			  {
      				  index_cpy--;
      				  HAL_Delay(200);

      			  }
      		  }

      		  if(BSP_JOY_GetState() == JOY_LEFT)
      		  {
      		 	BSP_LCD_GLASS_Clear();
      		 	tryb = 1;
      		  }

      		  if(BSP_JOY_GetState() == JOY_SEL)
      			 {
      			  for(int j = 0; j<100; j++)
      			  {
      				BSP_QSPI_Read(PlayBuff, WRITE_READ_ADDR+(BUFFER_SIZE*j)+(index_cpy-1)*BUFFER_SIZE*2, 2*BUFFER_SIZE);
      				if(PlaybackStarted == 0)
      				{
      					if(HAL_OK != HAL_SAI_Transmit_DMA(&hsai_BlockA1, (uint8_t *) &PlayBuff[0], 2*BUFFER_SIZE))
      					{
      						Error_Handler();
      					}
      					if(0 != audio_drv->Play(AUDIO_I2C_ADDRESS, (uint16_t *) &PlayBuff[0], 2*BUFFER_SIZE))
      					{
      						Error_Handler();
      					}
      					PlaybackStarted = 1;
      				}
      			  }
      			if(0 != audio_drv->Stop(AUDIO_I2C_ADDRESS, CODEC_PDWN_HW))
      					{
      				Error_Handler();
      					}
      			if(HAL_SAI_DMAStop(&hsai_BlockA1) != HAL_OK)
      			{
      				Error_Handler();
      			}
      			PlaybackStarted = 0;
      			  tryb = 1;
      			 }
      	  }
      	  while(tryb == 3)
      	  {
      		  if(BSP_JOY_GetState() == JOY_LEFT)
      		  {
      			  BSP_LCD_GLASS_Clear();
      			  tryb = 1;
      		  }

      		BSP_LCD_GLASS_ScrollSentence((uint8_t *)"      NAGRANIE.", 1, SCROLL_SPEED_HIGH);
      		BSP_LCD_GLASS_ScrollSentence((uint8_t *)"      NAGRANIE.", 1, SCROLL_SPEED_HIGH);
      		BSP_LCD_GLASS_ScrollSentence((uint8_t *)"      NAGRANIE.", 1, SCROLL_SPEED_HIGH);

      		for(int k = 0; k < 100; k++)
      		{
      		if(DmaRecHalfBuffCplt == 1)
      		{
      		      				      /* Store values on Play buff */
      			for(i = 0; i < BUFFER_SIZE/2; i++)
      			{
      				filter_arr[2*i]     = SaturaLH((RecBuff[i] >> 8), -32768, 32767);
      				filter_arr[(2*i)+1] = filter_arr[2*i];
      			}

      			DmaRecHalfBuffCplt  = 0;
      		}
      		if(DmaRecBuffCplt == 1)
      		{
      			/* Store values on Play buff */
      			for(i = BUFFER_SIZE/2; i < BUFFER_SIZE; i++)
      			{
      				filter_arr[2*i]     = SaturaLH((RecBuff[i] >> 8), -32768, 32767);
      				filter_arr[(2*i)+1] = filter_arr[2*i];
      			}

      			DmaRecBuffCplt  = 0;
      		}
      		if (BSP_QSPI_Write(filter_arr, WRITE_READ_ADDR+(BUFFER_SIZE*k*2)+index*100*2*BUFFER_SIZE, BUFFER_SIZE*2) != QSPI_OK) Error_Handler();
      		}

      		BSP_LED_On(LED_GREEN);
      		HAL_Delay(1000);
      		BSP_LED_Off(LED_GREEN);

      		tryb = 1;
      		index++;
      		index_cpy = index;
      	  }

        /* USER CODE END 3 */
      }
  /* USER CODE END 3 */
}

void SystemClock_Config(void)
{
  RCC_OscInitTypeDef RCC_OscInitStruct = {0};
  RCC_ClkInitTypeDef RCC_ClkInitStruct = {0};
  RCC_PeriphCLKInitTypeDef PeriphClkInit = {0};

  /** Configure LSE Drive Capability
  */
  HAL_PWR_EnableBkUpAccess();
  __HAL_RCC_LSEDRIVE_CONFIG(RCC_LSEDRIVE_LOW);
  /** Initializes the RCC Oscillators according to the specified parameters
  * in the RCC_OscInitTypeDef structure.
  */
  RCC_OscInitStruct.OscillatorType = RCC_OSCILLATORTYPE_LSI|RCC_OSCILLATORTYPE_LSE
                              |RCC_OSCILLATORTYPE_MSI;
  RCC_OscInitStruct.LSEState = RCC_LSE_ON;
  RCC_OscInitStruct.LSIState = RCC_LSI_ON;
  RCC_OscInitStruct.MSIState = RCC_MSI_ON;
  RCC_OscInitStruct.MSICalibrationValue = 0;
  RCC_OscInitStruct.MSIClockRange = RCC_MSIRANGE_6;
  RCC_OscInitStruct.PLL.PLLState = RCC_PLL_ON;
  RCC_OscInitStruct.PLL.PLLSource = RCC_PLLSOURCE_MSI;
  RCC_OscInitStruct.PLL.PLLM = 1;
  RCC_OscInitStruct.PLL.PLLN = 40;
  RCC_OscInitStruct.PLL.PLLP = RCC_PLLP_DIV7;
  RCC_OscInitStruct.PLL.PLLQ = RCC_PLLQ_DIV4;
  RCC_OscInitStruct.PLL.PLLR = RCC_PLLR_DIV2;
  if (HAL_RCC_OscConfig(&RCC_OscInitStruct) != HAL_OK)
  {
    Error_Handler();
  }
  /** Initializes the CPU, AHB and APB buses clocks
  */
  RCC_ClkInitStruct.ClockType = RCC_CLOCKTYPE_HCLK|RCC_CLOCKTYPE_SYSCLK
                              |RCC_CLOCKTYPE_PCLK1|RCC_CLOCKTYPE_PCLK2;
  RCC_ClkInitStruct.SYSCLKSource = RCC_SYSCLKSOURCE_PLLCLK;
  RCC_ClkInitStruct.AHBCLKDivider = RCC_SYSCLK_DIV2;
  RCC_ClkInitStruct.APB1CLKDivider = RCC_HCLK_DIV1;
  RCC_ClkInitStruct.APB2CLKDivider = RCC_HCLK_DIV1;

  if (HAL_RCC_ClockConfig(&RCC_ClkInitStruct, FLASH_LATENCY_2) != HAL_OK)
  {
    Error_Handler();
  }
  PeriphClkInit.PeriphClockSelection = RCC_PERIPHCLK_RTC|RCC_PERIPHCLK_USART2
                              |RCC_PERIPHCLK_SAI1|RCC_PERIPHCLK_I2C1
                              |RCC_PERIPHCLK_I2C2|RCC_PERIPHCLK_DFSDM1
                              |RCC_PERIPHCLK_USB;
  PeriphClkInit.Usart2ClockSelection = RCC_USART2CLKSOURCE_PCLK1;
  PeriphClkInit.I2c1ClockSelection = RCC_I2C1CLKSOURCE_PCLK1;
  PeriphClkInit.I2c2ClockSelection = RCC_I2C2CLKSOURCE_PCLK1;
  PeriphClkInit.Sai1ClockSelection = RCC_SAI1CLKSOURCE_PLLSAI1;
  PeriphClkInit.Dfsdm1ClockSelection = RCC_DFSDM1CLKSOURCE_PCLK;
  PeriphClkInit.RTCClockSelection = RCC_RTCCLKSOURCE_LSI;
  PeriphClkInit.UsbClockSelection = RCC_USBCLKSOURCE_PLLSAI1;
  PeriphClkInit.PLLSAI1.PLLSAI1Source = RCC_PLLSOURCE_MSI;
  PeriphClkInit.PLLSAI1.PLLSAI1M = 1;
  PeriphClkInit.PLLSAI1.PLLSAI1N = 48;
  PeriphClkInit.PLLSAI1.PLLSAI1P = RCC_PLLP_DIV17;
  PeriphClkInit.PLLSAI1.PLLSAI1Q = RCC_PLLQ_DIV4;
  PeriphClkInit.PLLSAI1.PLLSAI1R = RCC_PLLR_DIV2;
  PeriphClkInit.PLLSAI1.PLLSAI1ClockOut = RCC_PLLSAI1_SAI1CLK|RCC_PLLSAI1_48M2CLK;
  if (HAL_RCCEx_PeriphCLKConfig(&PeriphClkInit) != HAL_OK)
  {
    Error_Handler();
  }
  /** Configure the main internal regulator output voltage
  */
  if (HAL_PWREx_ControlVoltageScaling(PWR_REGULATOR_VOLTAGE_SCALE1) != HAL_OK)
  {
    Error_Handler();
  }
  /** Enable MSI Auto calibration
  */
  HAL_RCCEx_EnableMSIPLLMode();
}

/* USER CODE BEGIN 4 */
void HAL_DFSDM_FilterRegConvHalfCpltCallback(DFSDM_Filter_HandleTypeDef *hdfsdm1_filter0)
{

	DmaRecHalfBuffCplt = 1;

}

void HAL_DFSDM_FilterRegConvCpltCallback(DFSDM_Filter_HandleTypeDef *hdfsdm1_filter0)
{

  DmaRecBuffCplt = 1;

}

/* USER CODE END 4 */

void Error_Handler(void)
{
  /* USER CODE BEGIN Error_Handler_Debug */
  /* User can add his own implementation to report the HAL error return state */
	 while (1)
	  {
		  BSP_LED_Toggle(LED4);
		  HAL_Delay(1000);
	  }
  /* USER CODE END Error_Handler_Debug */
}

/************************ (C) COPYRIGHT STMicroelectronics *****END OF FILE****/
